# LKS32MC08x register map
Vendor: Linko Ltd.; Series: LKS32MC08x; File version: 1.0
CPU: CM0 r1p0, little endian, MPU, no FPU, 3 interrupt priority bits
Registers are 32-bit, read-write, reset 0x0 unless marked. A register's access mark holds for its fields unless they carry their own. Offsets are from the block's base; [hi:lo] are bit positions; {n}, {i} and the like mark numbered series.

## CRC — CRC registers
Base 0x40012400
0x00 CRC_DR — CRC data
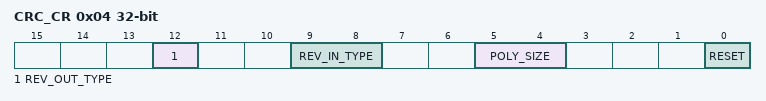
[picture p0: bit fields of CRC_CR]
0x04 CRC_CR — CRC control
  [12] REV_OUT_TYPE — output reversed
  [9:8] REV_IN_TYPE — input reversed
    0=NO_REV (no reverse); 1=BYTE_REV (byte reversed); 2=HALFWORD_REV (halfword reversed); 3=WORD_REV (word reversed)
  [5:4] POLY_SIZE — crc result output bit width
    0=32BITS; 1=16BITS; 2=8BITS; 3=7BITS
  [0] RESET wo — reset crc chain to use CRC_INIT as initial value in crc calculation
    0=LAST (Use last crc result as crc initial value); 1=INIT (Use CRC_INIT as crc initial value)
0x08 CRC_INIT reset 0xFFFFFFFF — CRC initial value
0x0C CRC_POL — CRC coefficient

## UART0 — UART0 registers
Base 0x40012800
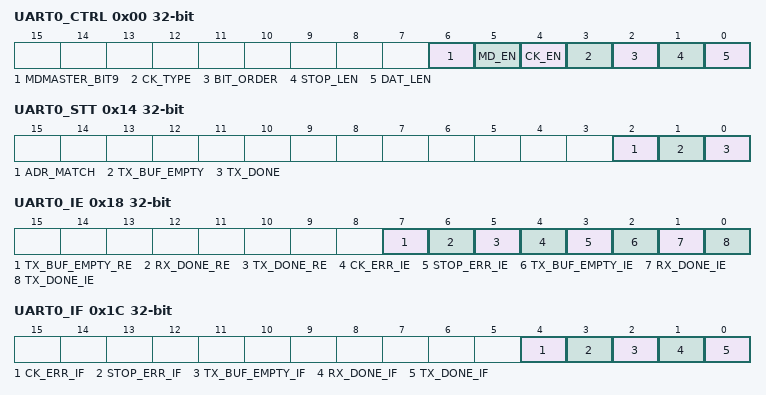
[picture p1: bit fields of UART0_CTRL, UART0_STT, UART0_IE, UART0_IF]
0x00 UART0_CTRL — UART control
  [6] MDMASTER_BIT9 — The 9th bit value in multi-drop master mode
    0=L (The 9th bit is 0); 1=H (The 9th bit is 1)
  [5] MD_EN — Multi-drop mode enable
    0=Disabled (Multi-drop mode disabled); 1=Enabled (Multi-drop mode enabled)
  [4] CK_EN — Odd-Even Check enable
    0=Disabled (Odd-Even check disabled); 1=Enabled (Odd-Even check enabled)
  [3] CK_TYPE — Odd or Even Check
    0=EVEN (Even check); 1=ODD (Odd check)
  [2] BIT_ORDER — LSB or MSB
    0=LSB; 1=MSB
  [1] STOP_LEN — Stop bit length
    0=1B (1bit stop bit); 1=2B (2bit stop bit)
  [0] DAT_LEN — Data length
    0=8B (8bit data); 1=7B (7bit data)
0x04 UART0_DIVH — UART Baudrate higher byte
0x08 UART0_DIVL — UART Baudrate lower byte
0x0C UART0_BUFF — UART read/write buffer
0x10 UART0_ADR — UART match address as RS485
0x14 UART0_STT — UART status
  [2] ADR_MATCH — Address matched in multi-drop mode
  [1] TX_BUF_EMPTY — TX Buffer empty
  [0] TX_DONE — Transmission fnished
0x18 UART0_IE — UART interrupt enable
  [7] TX_BUF_EMPTY_RE — TX Buffer empty DMA request enable
  [6] RX_DONE_RE — Byte received DMA request enable
  [5] TX_DONE_RE — Byte transmission finished DMA request flag
  [4] CK_ERR_IE — Check error interrupt enable
  [3] STOP_ERR_IE — Stop bit error interrupt enable
  [2] TX_BUF_EMPTY_IE — TX Buffer empty interrupt enable
  [1] RX_DONE_IE — Byte received interrupt enable
  [0] TX_DONE_IE — Byte transmission finished interrupt flag
0x1C UART0_IF — UART interrupt flag
  [4] CK_ERR_IF — Check error interrupt flag
  [3] STOP_ERR_IF — Stop bit error interrupt flag
  [2] TX_BUF_EMPTY_IF — TX Buffer empty interrupt flag
  [1] RX_DONE_IF — Byte received interrupt flag
  [0] TX_DONE_IF — Byte transmission finished interrupt flag
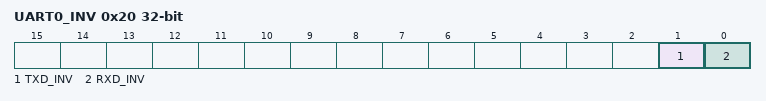
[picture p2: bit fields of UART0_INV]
0x20 UART0_INV — UART IO inverted
  [1] TXD_INV — TXD inverted then output
  [0] RXD_INV — RXD inverted then input

## UART1 — UART1 registers
Base 0x40012C00
Registers as UART0 (with UART0 read as UART1).

## DMA — DMA registers
Base 0x40013000
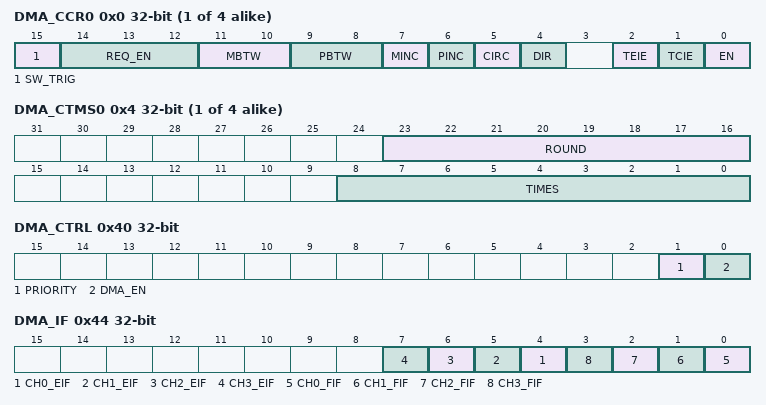
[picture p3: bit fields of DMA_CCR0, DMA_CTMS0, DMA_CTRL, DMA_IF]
{0x0+0x10*i} DMA_CCR{i} (i=0..3) — DMA channel {i} configuration
  [15] SW_TRIG — software trigger
  [14:12] REQ_EN — channel request enable
  [11:10] MBTW — Memory bit width
  [9:8] PBTW — Peripheral bit width
  [7] MINC — Memory Address Incremental
  [6] PINC — Peripheral Address Incremental
  [5] CIRC — circular mode
  [4] DIR — transmission direction
  [2] TEIE — transmission error interrupt enable
  [1] TCIE — transmission finish interrupt enable
  [0] EN — channel enable
{0x4+0x10*i} DMA_CTMS{i} (i=0..3) — DMA channel {i} transmission times
  [23:16] ROUND — transmission round number
  [8:0] TIMES — times per round
{0x8+0x10*i} DMA_CPAR{i} (i=0..3) — DMA channel {i} peripheral address
  [16:0] PERI_ADDR — Peripheral Address Incremental
{0xC+0x10*i} DMA_CMAR{i} (i=0..3) — DMA channel {i} memory address
  [12:0] MEM_ADDR — Memory Address Incremental
0x40 DMA_CTRL — DMA control
  [1] PRIORITY — CPU/DMA priority
    0=CPU_higher (CPU priority is higher); 1=DMA_higher (DMA priority is higher)
  [0] DMA_EN — DMA enable
    0=DISABLED (DMA is disabled); 1=ENABLED (DMA is enabled)
0x44 DMA_IF — DMA interrupt flag
  [n+4] CH{n}_EIF (n=0..3) — channel {n} error interrupt flag
  [n] CH{n}_FIF (n=0..3) — channel {n} transmission finish interrupt flag

## SIF — SIF registers
Base 0x40013800
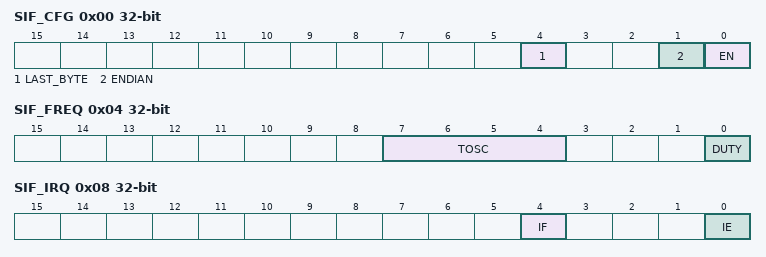
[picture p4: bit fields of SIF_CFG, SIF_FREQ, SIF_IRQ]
0x00 SIF_CFG — SIF configuration register
  [4] LAST_BYTE — Is this the last byte of the current transfer
  [1] ENDIAN — SIF LSB/MSB first
    0=LSB (LSB first); 1=MSB (MSB first)
  [0] EN — SIF module Enable
    0=DISABLED (SIF module is disabled); 1=ENABLED (SIF module is enabled)
0x04 SIF_FREQ — SIF frequency register
  [7:4] TOSC — Base Timer Unit
    1=32us (Tosc is 32us); 2=64us (Tosc is 64us); 3=96us (Tosc is 96us); 4=128us (Tosc is 128us); 5=160us (Tosc is160us); 6=192us (Tosc is 192us); 7=220us (Tosc is 220us); 8=256us (Tosc is 256us); 9=288us (Tosc is 288us); 10=320us (Tosc is 320us)
  [0] DUTY — Data duty cycle
    0=2_to_1 (Duty cycle is 2/1); 1=3_to_1 (Duty cycle is 3/1)
0x08 SIF_IRQ — SIF interrupt register
  [4] IF — Interrupt Flag
    0=Clear (SIF interrupt is cleared); 1=Set (SIF interrupt is set)
  [0] IE — Interrupt Enable
    0=DISABLED (SIF interrupt is disabled); 1=ENABLED (SIF interrupt is enabled)
0x0C SIF_WDATA — SIF write data register, write to start transmission

## DSP — DSP registers
Base 0x40014000
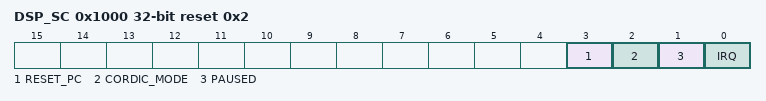
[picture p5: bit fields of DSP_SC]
0x1000 DSP_SC reset 0x2 — DSP dividend
  [3] RESET_PC wo — Reset DSP PC
  [2] CORDIC_MODE — SINCOS/ARCTAN
  [1] PAUSED — DSP paused
  [0] IRQ — DSP IRQ, write one to clear
0x1004 DSP_THETA — theta for cordic
0x1008 DSP_X — coordinate x of cordic
0x100C DSP_Y — coordinate y of cordic
0x1010 DSP_SIN ro — sin of cordic
0x1014 DSP_COS ro — cos of cordic
0x1018 DSP_MOD ro — module of cordic
0x101C DSP_ARCTAN ro — arctan of cordic
0x1020 DSP_DID — DSP dividend
0x1024 DSP_DIS — DSP divider (Should NOT be zero)
0x1028 DSP_QUO ro — DSP quotient
0x102C DSP_REM ro — DSP remainder
0x1030 DSP_RAD — DSP radicand
0x1034 DSP_SQRT 16-bit ro — DSP square root
